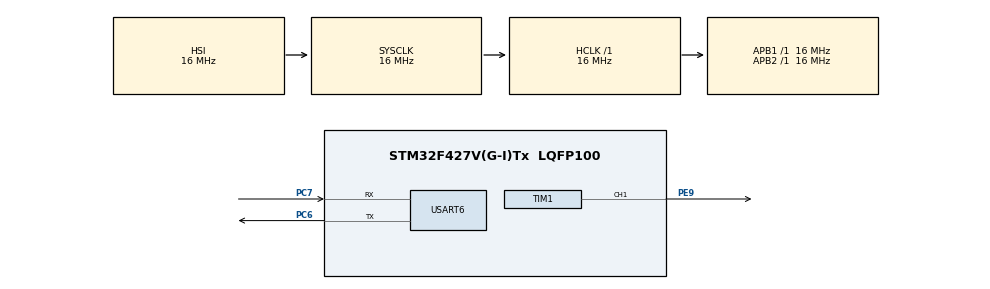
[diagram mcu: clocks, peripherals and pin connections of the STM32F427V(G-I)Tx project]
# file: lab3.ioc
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Mcu.Family=STM32F4
Mcu.Name=STM32F427V(G-I)Tx
Mcu.Package=LQFP100
NVIC.PriorityGroup=NVIC_PRIORITYGROUP_4
NVIC.TIM6_DAC_IRQn=true\:0\:0\:false\:false\:true\:true\:true\:true
NVIC.USART6_IRQn=true\:0\:0\:false\:false\:true\:true\:true\:true
PA13.Mode=JTAG_5_pins
PA13.Signal=SYS_JTMS-SWDIO
PA14.Mode=JTAG_5_pins
PA14.Signal=SYS_JTCK-SWCLK
PA15.Mode=JTAG_5_pins
PA15.Signal=SYS_JTDI
PB3.Mode=JTAG_5_pins
PB3.Signal=SYS_JTDO-SWO
PB4.Mode=JTAG_5_pins
PB4.Signal=SYS_JTRST
PC6.Mode=Asynchronous
PC6.Signal=USART6_TX
PC7.Mode=Asynchronous
PC7.Signal=USART6_RX
PE9.Signal=S_TIM1_CH1
ProjectManager.HeapSize=0x200
ProjectManager.StackSize=0x400
ProjectManager.TargetToolchain=STM32CubeIDE
RCC.48MHZClocksFreq_Value=48000000
RCC.AHBFreq_Value=16000000
RCC.APB1Freq_Value=16000000
RCC.APB1TimFreq_Value=16000000
RCC.APB2Freq_Value=16000000
RCC.APB2TimFreq_Value=16000000
RCC.CortexFreq_Value=16000000
RCC.HCLKFreq_Value=16000000
RCC.HSE_VALUE=25000000
RCC.HSI_VALUE=16000000
RCC.LSE_VALUE=32768
RCC.SYSCLKFreq_VALUE=16000000
RCC.VCOOutputFreq_Value=192000000
SH.S_TIM1_CH1.0=TIM1_CH1,PWM Generation1 CH1
TIM1.Channel-PWM\ Generation1\ CH1=TIM_CHANNEL_1
TIM1.Period=10
TIM1.Prescaler=0
TIM1.Pulse-PWM\ Generation1\ CH1=0
TIM6.AutoReloadPreload=TIM_AUTORELOAD_PRELOAD_DISABLE
TIM6.Period=1000
TIM6.Prescaler=15999
USART6.VirtualMode=VM_ASYNC
VP_TIM1_VS_ClockSourceINT.Mode=Internal
VP_TIM6_VS_ClockSourceINT.Mode=Enable_Timer
board=custom

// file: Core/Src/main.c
/* USER CODE BEGIN Header */
/**
  ******************************************************************************
  * @file           : main.c
  * @brief          : Main program body
  ******************************************************************************
  * @attention
  *
  * Copyright (c) 2022 STMicroelectronics.
  * All rights reserved.
  *
  * This software is licensed under terms that can be found in the LICENSE file
  * in the root directory of this software component.
  * If no LICENSE file comes with this software, it is provided AS-IS.
  *
  ******************************************************************************
  */
/* USER CODE END Header */
#include "main.h"
#include "tim.h"
#include "usart.h"
#include "gpio.h"

/* USER CODE BEGIN Includes */
#include <string.h>
#include <stdio.h>
#include <inttypes.h>

#include "command.h"
#include "menu.h"
#include "hardware/buzzer.h"
/* USER CODE END Includes */

/* USER CODE BEGIN PD */
#define UART_BUF_SIZE 128
/* USER CODE END PD */

/* USER CODE BEGIN PV */
static uint8_t uartBuf[UART_BUF_SIZE];
static uint8_t uartBufLast = 0;
static Command *commands[12];
/* USER CODE END PV */

void SystemClock_Config(void);
/* USER CODE BEGIN PFP */
static void sendMessage(const char * msg);
static void receiveAndSendChar();
static void sendCommandResult(const char * commandResult);
/* USER CODE END PFP */

int main(void)
{
  /* USER CODE BEGIN 1 */
	  commands[0] = commandCreate("1", (CommandAction) playA);
	  commands[1] = commandCreate("2", (CommandAction) playB);
	  commands[2] = commandCreate("3", (CommandAction) playC);
	  commands[3] = commandCreate("4", (CommandAction) playD);
	  commands[4] = commandCreate("5", (CommandAction) playE);
	  commands[5] = commandCreate("6", (CommandAction) playF);
	  commands[6] = commandCreate("7", (CommandAction) playG);
	  commands[7] = commandCreate("+", (CommandAction) upOctave);
	  commands[8] = commandCreate("-", (CommandAction) downOctave);
	  commands[9] = commandCreate("A", (CommandAction) upDuration);
	  commands[10] = commandCreate("a", (CommandAction) downDuration);
	  commands[11] = commandCreate("\r", (CommandAction) playAll);
  /* USER CODE END 1 */

  /* MCU Configuration--------------------------------------------------------*/

  /* Reset of all peripherals, Initializes the Flash interface and the Systick. */
  HAL_Init();

  /* Configure the system clock */
  SystemClock_Config();

  /* Initialize all configured peripherals */
  MX_GPIO_Init();
  MX_USART6_UART_Init();
  MX_TIM1_Init();
  MX_TIM6_Init();
  /* USER CODE BEGIN 2 */
  uartInit();
  HAL_TIM_PWM_Start(&htim1, TIM_CHANNEL_1);
  HAL_TIM_Base_Start_IT(&htim6);
  menuInit(commands, 12);
  sendMessage("Started\n");
  /* USER CODE END 2 */

  /* Infinite loop */
  /* USER CODE BEGIN WHILE */
  while (1)
  {
	  uartPolling();

	  if (uartHasNext()) {
		  receiveAndSendChar();
	  }

    /* USER CODE END WHILE */

  }
}

void SystemClock_Config(void)
{
  RCC_OscInitTypeDef RCC_OscInitStruct = {0};
  RCC_ClkInitTypeDef RCC_ClkInitStruct = {0};

  /** Configure the main internal regulator output voltage
  */
  __HAL_RCC_PWR_CLK_ENABLE();
  __HAL_PWR_VOLTAGESCALING_CONFIG(PWR_REGULATOR_VOLTAGE_SCALE3);

  /** Initializes the RCC Oscillators according to the specified parameters
  * in the RCC_OscInitTypeDef structure.
  */
  RCC_OscInitStruct.OscillatorType = RCC_OSCILLATORTYPE_HSI;
  RCC_OscInitStruct.HSIState = RCC_HSI_ON;
  RCC_OscInitStruct.HSICalibrationValue = RCC_HSICALIBRATION_DEFAULT;
  RCC_OscInitStruct.PLL.PLLState = RCC_PLL_NONE;
  if (HAL_RCC_OscConfig(&RCC_OscInitStruct) != HAL_OK)
  {
    Error_Handler();
  }

  /** Initializes the CPU, AHB and APB buses clocks
  */
  RCC_ClkInitStruct.ClockType = RCC_CLOCKTYPE_HCLK|RCC_CLOCKTYPE_SYSCLK
                              |RCC_CLOCKTYPE_PCLK1|RCC_CLOCKTYPE_PCLK2;
  RCC_ClkInitStruct.SYSCLKSource = RCC_SYSCLKSOURCE_HSI;
  RCC_ClkInitStruct.AHBCLKDivider = RCC_SYSCLK_DIV1;
  RCC_ClkInitStruct.APB1CLKDivider = RCC_HCLK_DIV1;
  RCC_ClkInitStruct.APB2CLKDivider = RCC_HCLK_DIV1;

  if (HAL_RCC_ClockConfig(&RCC_ClkInitStruct, FLASH_LATENCY_0) != HAL_OK)
  {
    Error_Handler();
  }
}

/* USER CODE BEGIN 4 */
static void sendMessage(const char * msg) {
    uartTransmit((uint8_t *) msg, strlen(msg));
}

static void receiveAndSendChar() {
    if (uartReceive(uartBuf + uartBufLast, 1)) {
        uint8_t received = uartBuf[uartBufLast];
        uartBufLast++;
        uartTransmit(&received, 1);

        uartBuf[uartBufLast] = '\0';
        const char *commandResult = menuExecuteCommand((char *) uartBuf);
        sendMessage("\n");
        sendCommandResult(commandResult);
    }
}

static void sendCommandResult(const char * commandResult) {
    uartTransmit((uint8_t *) commandResult, strlen(commandResult));
    uartBufLast = 0;
}
/* USER CODE END 4 */

void Error_Handler(void)
{
  __disable_irq();
  while (1)
  {
  }
}
